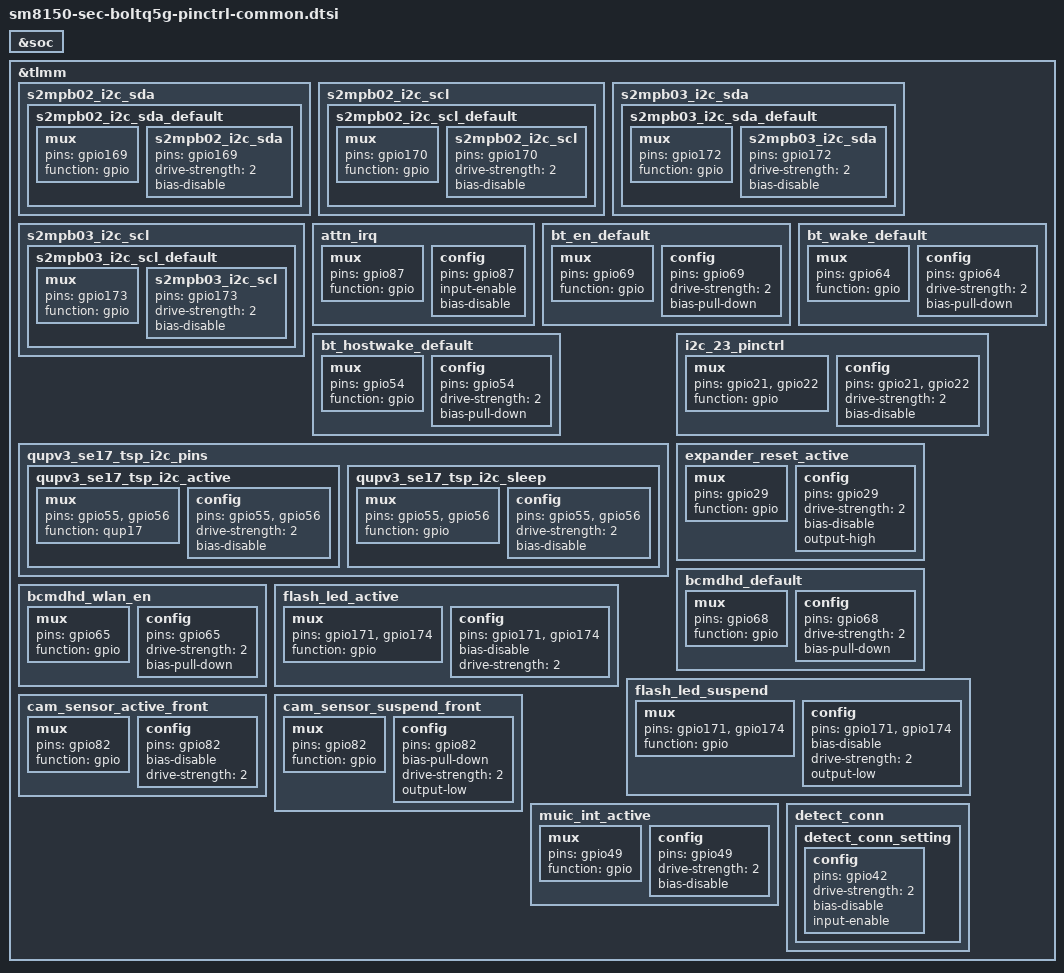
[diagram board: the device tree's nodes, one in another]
/* Copyright (c) 2016-2018, The Linux Foundation. All rights reserved.
 *
 * This program is free software; you can redistribute it and/or modify
 * it under the terms of the GNU General Public License version 2 and
 * only version 2 as published by the Free Software Foundation.
 *
 * This program is distributed in the hope that it will be useful,
 * but WITHOUT ANY WARRANTY; without even the implied warranty of
 * MERCHANTABILITY or FITNESS FOR A PARTICULAR PURPOSE.  See the
 * GNU General Public License for more details.
 */

&soc {
};

&tlmm {
	s2mpb02_i2c_sda {
		s2mpb02_i2c_sda_default: s2mpb02_i2c_sda_default {
			mux {
				pins = "gpio169";
				function = "gpio";
			};
			s2mpb02_i2c_sda {
				pins = "gpio169";
				drive-strength = <2>;
				bias-disable;
			};
		};
	};
	s2mpb02_i2c_scl {
		s2mpb02_i2c_scl_default: s2mpb02_i2c_scl_default {
			mux {
				pins = "gpio170";
				function = "gpio";
			};
			s2mpb02_i2c_scl {
				pins = "gpio170";
				drive-strength = <2>;
				bias-disable;
			};
		};
	};

	s2mpb03_i2c_sda {
		s2mpb03_i2c_sda_default: s2mpb03_i2c_sda_default {
			mux {
				pins = "gpio172";
				function = "gpio";
			};
			s2mpb03_i2c_sda {
				pins = "gpio172";
				drive-strength = <2>;
				bias-disable;
			};
		};
	};
	s2mpb03_i2c_scl {
		s2mpb03_i2c_scl_default: s2mpb03_i2c_scl_default {
			mux {
				pins = "gpio173";
				function = "gpio";
			};
			s2mpb03_i2c_scl {
				pins = "gpio173";
				drive-strength = <2>;
				bias-disable;
			};
		};
	};

	attn_irq: attn_irq {
		mux {
			pins = "gpio87";
			function = "gpio";
		};
		config {
			pins = "gpio87";
			input-enable;
			bias-disable;
		};
	};

	bt_en_default: bt_en_default {
		mux {
			pins = "gpio69";
			function = "gpio";
		};
		config {
			pins = "gpio69";
			drive-strength = <2>;
			bias-pull-down;
		};
	};
	bt_wake_default: bt_wake_default {
		mux {
			pins = "gpio64";
			function = "gpio";
		};
		config {
			pins = "gpio64";
			drive-strength = <2>;
			bias-pull-down;
		};
	};
	bt_hostwake_default: bt_hostwake_default {
		mux {
			pins = "gpio54";
			function = "gpio";
		};
		config {
			pins = "gpio54";
			drive-strength = <2>;
			bias-pull-down;
		};
	};

#if 0
	muic_i2c {
		muic_i2c_active: muic_i2c_active {
			muic_i2c {
				pins = "gpio25", "gpio26";
				drive-strength = <2>;
				bias-disable;
			};
		};
		muic_i2c_suspend: muic_i2c_suspend {
			muic_i2c {
				pins = "gpio25", "gpio26";
				drive-strength = <2>;
				bias-disable;
			};
		};
	};

        jig_irq {
                jig_irq_active: jig_irq_active {
                        jig_irq_active {
                                pins = "gpio120";
                                drive-strength = <2>;
                                bias-disable;
                                input-enable;
                        };
                };
                jig_irq_suspend: jig_irq_suspend {
                        jig_irq_suspend {
                                pins = "gpio120";
                                drive-strength = <2>;
                                bias-disable;
                                input-enable;
                        };
                };
        };
#endif
	/* SE 17 pin mappings */
	qupv3_se17_tsp_i2c_pins: qupv3_se17_tsp_i2c_pins {
		qupv3_se17_tsp_i2c_active: qupv3_se17_tsp_i2c_active {
			mux {
				pins = "gpio55", "gpio56";
				function = "qup17";
			};

			config {
				pins = "gpio55", "gpio56";
				drive-strength = <2>;
				bias-disable;
			};
		};

		qupv3_se17_tsp_i2c_sleep: qupv3_se17_tsp_i2c_sleep {
			mux {
				pins = "gpio55", "gpio56";
				function = "gpio";
			};

			config {
				pins = "gpio55", "gpio56";
				drive-strength = <2>;
				bias-disable;
			};
		};
	};

	i2c_23_pinctrl: i2c_23_pinctrl {
		mux {
			pins = "gpio21",	/* EXPANDER_I2C_SDA_1P8 */
			       "gpio22";	/* EXPANDER_I2C_SCL_1P8 */
			function = "gpio";
		};
		config {
			pins = "gpio21",	/* EXPANDER_I2C_SDA_1P8 */
			       "gpio22";	/* EXPANDER_I2C_SCL_1P8 */
			drive-strength = <2>;
			bias-disable;
		};
	};

	expander_reset_active: expander_reset_active {
		mux {
			pins = "gpio29";
			function = "gpio";
		};
		config {
			pins = "gpio29";
			drive-strength = <2>;   /* 16 mA */
			bias-disable;
			output-high;
		};
	};

	bcmdhd_default: bcmdhd_default {
		mux {
			pins = "gpio68";
			function = "gpio";
		};
		config {
			pins = "gpio68";
			drive-strength = <2>;   /* 2 mA */
			bias-pull-down;         /* PULL DOWN */
		};
	};

	bcmdhd_wlan_en: bcmdhd_wlan_en {
		mux {
			pins = "gpio65";
			function = "gpio";
		};
		config {
			pins = "gpio65";
			drive-strength = <2>;   /* 2 mA */
			bias-pull-down;         /* PULL DOWN */
		};
	};

	flash_led_active: flash_led_active {
		mux {
			pins = "gpio171","gpio174";
			function = "gpio";
		};

		config {
			pins = "gpio171","gpio174";
			bias-disable; /* No PULL */
			drive-strength = <2>; /* 2 MA */
		};
	};

	flash_led_suspend: flash_led_suspend {
		mux {
			pins = "gpio171","gpio174";
			function = "gpio";
		};

		config {
			pins = "gpio171","gpio174";
			bias-disable; /* No PULL */
			drive-strength = <2>; /* 2 MA */
			output-low;
		};
	};

	cam_sensor_active_front: cam_sensor_active_front {
		/* RESET FRONT */
		mux {
			pins = "gpio82";
			function = "gpio";
		};

		config {
			pins = "gpio82";
			bias-disable; /* No PULL */
			drive-strength = <2>; /* 2 MA */
		};
	};

	cam_sensor_suspend_front: cam_sensor_suspend_front {
		/* RESET FRONT */
		mux {
			pins = "gpio82";
			function = "gpio";
		};

		config {
			pins = "gpio82";
			bias-pull-down; /* PULL DOWN */
			drive-strength = <2>; /* 2 MA */
			output-low;
		};
	};

	muic_int_active: muic_int_active {
		mux {
			pins = "gpio49";
	 		function = "gpio";
	 	};
		config {
	 		pins = "gpio49";
/*	 		input-enable;*/
/*	 		bias-pull-up;*/
			drive-strength = <2>;
			bias-disable;

	 	};
	};

	detect_conn {
		detect_conn_setting: detect_conn_setting {
			config {
				pins = "gpio42";
				drive-strength = <2>;
				bias-disable; /* No PULL */
				input-enable;
			};
		};
	};
};


